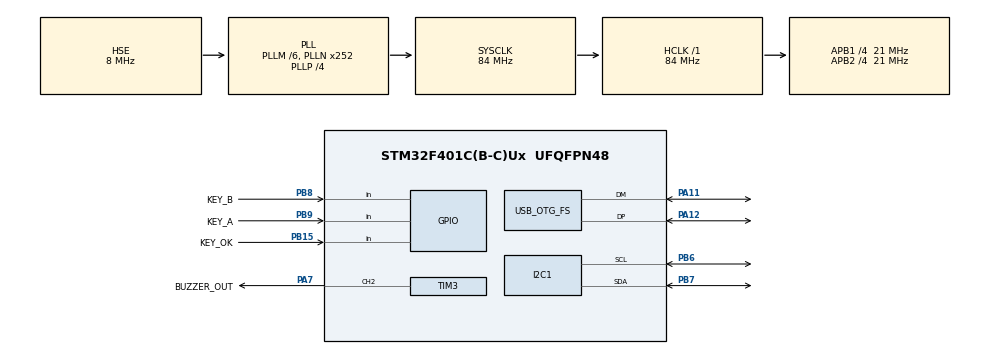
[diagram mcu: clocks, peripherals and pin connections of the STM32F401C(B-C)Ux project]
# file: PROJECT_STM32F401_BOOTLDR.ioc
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Dma.I2C1_RX.0.Direction=DMA_PERIPH_TO_MEMORY
Dma.I2C1_RX.0.FIFOMode=DMA_FIFOMODE_DISABLE
Dma.I2C1_RX.0.Instance=DMA1_Stream0
Dma.I2C1_RX.0.MemDataAlignment=DMA_MDATAALIGN_BYTE
Dma.I2C1_RX.0.MemInc=DMA_MINC_ENABLE
Dma.I2C1_RX.0.Mode=DMA_NORMAL
Dma.I2C1_RX.0.PeriphDataAlignment=DMA_PDATAALIGN_BYTE
Dma.I2C1_RX.0.PeriphInc=DMA_PINC_DISABLE
Dma.I2C1_RX.0.Priority=DMA_PRIORITY_LOW
Dma.I2C1_TX.1.Direction=DMA_MEMORY_TO_PERIPH
Dma.I2C1_TX.1.FIFOMode=DMA_FIFOMODE_DISABLE
Dma.I2C1_TX.1.Instance=DMA1_Stream6
Dma.I2C1_TX.1.MemDataAlignment=DMA_MDATAALIGN_BYTE
Dma.I2C1_TX.1.MemInc=DMA_MINC_ENABLE
Dma.I2C1_TX.1.Mode=DMA_NORMAL
Dma.I2C1_TX.1.PeriphDataAlignment=DMA_PDATAALIGN_BYTE
Dma.I2C1_TX.1.PeriphInc=DMA_PINC_DISABLE
Dma.I2C1_TX.1.Priority=DMA_PRIORITY_MEDIUM
Dma.Request0=I2C1_RX
Dma.Request1=I2C1_TX
I2C1.I2C_Mode=I2C_Fast
Mcu.Family=STM32F4
Mcu.Name=STM32F401C(B-C)Ux
Mcu.Package=UFQFPN48
Mcu.UserConstants=TREF_TEMP_ADC1_CHANNEL,ADC_CHANNEL_2;TEMP_TEMP_ADC1_CHANNEL,ADC_CHANNEL_8;TIM1_PSC_FAST_PWM,46978;TIM1_PSC_SLOW_PWM,65535;BUZZER_CHANNEL,TIM_CHANNEL_2;SCL1_Pin,GPIO_PIN_6;SDA1_Pin,GPIO_PIN_7;SCL1_GPIO_Port,GPIOB;SDA1_GPIO_Port,GPIOB;SCL3_Pin,GPIO_PIN_8;SDA3_Pin,GPIO_PIN_4;SCL3_GPIO_Port,GPIOA;SDA3_GPIO_Port,GPIOB
NVIC.DMA1_Stream0_IRQn=true\:5\:0\:true\:false\:true\:false\:true
NVIC.DMA1_Stream6_IRQn=true\:5\:0\:true\:false\:true\:false\:true
NVIC.I2C1_ER_IRQn=true\:15\:0\:true\:false\:true\:true\:true
NVIC.I2C1_EV_IRQn=true\:15\:0\:true\:false\:true\:true\:true
NVIC.OTG_FS_IRQn=true\:5\:0\:true\:false\:true\:true\:true
NVIC.PriorityGroup=NVIC_PRIORITYGROUP_4
NVIC.TIM3_IRQn=true\:0\:0\:false\:false\:true\:true\:true
NVIC.TIM4_IRQn=true\:0\:0\:false\:false\:true\:false\:true
NVIC.TimeBase=TIM4_IRQn
NVIC.TimeBaseIP=TIM4
PA11.Mode=Device_Only
PA11.Signal=USB_OTG_FS_DM
PA12.Mode=Device_Only
PA12.Signal=USB_OTG_FS_DP
PA13.Mode=Serial_Wire
PA13.Signal=SYS_JTMS-SWDIO
PA14.Mode=Serial_Wire
PA14.Signal=SYS_JTCK-SWCLK
PA7.GPIO_Label=BUZZER_OUT
PA7.GPIO_Speed=GPIO_SPEED_FREQ_HIGH
PA7.Signal=S_TIM3_CH2
PB15.GPIO_Label=KEY_OK
PB15.GPIO_PuPd=GPIO_PULLUP
PB15.Signal=GPIO_Input
PB6.GPIO_Pu=GPIO_PULLUP
PB6.Mode=I2C
PB6.Signal=I2C1_SCL
PB7.GPIO_Pu=GPIO_PULLUP
PB7.Mode=I2C
PB7.Signal=I2C1_SDA
PB8.GPIO_Label=KEY_B
PB8.Signal=GPIO_Input
PB9.GPIO_Label=KEY_A
PB9.GPIO_PuPd=GPIO_PULLUP
PB9.Signal=GPIO_Input
PH0\ -\ OSC_IN.Mode=HSE-External-Oscillator
PH0\ -\ OSC_IN.Signal=RCC_OSC_IN
PH1\ -\ OSC_OUT.Mode=HSE-External-Oscillator
PH1\ -\ OSC_OUT.Signal=RCC_OSC_OUT
ProjectManager.HeapSize=0x900
ProjectManager.StackSize=0x900
ProjectManager.TargetToolchain=STM32CubeIDE
RCC.48MHZClocksFreq_Value=48000000
RCC.AHBFreq_Value=84000000
RCC.APB1CLKDivider=RCC_HCLK_DIV4
RCC.APB1Freq_Value=21000000
RCC.APB1TimFreq_Value=42000000
RCC.APB2CLKDivider=RCC_HCLK_DIV4
RCC.APB2Freq_Value=21000000
RCC.APB2TimFreq_Value=42000000
RCC.CortexFreq_Value=84000000
RCC.HCLKFreq_Value=84000000
RCC.HSE_VALUE=8000000
RCC.HSI_VALUE=16000000
RCC.LSE_VALUE=32768
RCC.PLLM=6
RCC.PLLN=252
RCC.PLLP=RCC_PLLP_DIV4
RCC.PLLQ=7
RCC.SYSCLKFreq_VALUE=84000000
RCC.SYSCLKSource=RCC_SYSCLKSOURCE_PLLCLK
RCC.VCOOutputFreq_Value=336000000
SH.S_TIM3_CH2.0=TIM3_CH2,PWM Generation2 CH2
TIM3.Channel-PWM\ Generation2\ CH2=TIM_CHANNEL_2
TIM3.OCPolarity_2=TIM_OCPOLARITY_LOW
TIM3.Period=255
TIM3.Prescaler=41
USB_DEVICE.CLASS_NAME_FS=DFU
USB_DEVICE.USBD_DFU_APP_DEFAULT_ADD=0x08010000
USB_DEVICE.USBD_DFU_MEDIA=@Internal Flash   /0x08000000/03*016Ka,01*016Kg,01*064Kg,07*128Kg
USB_DEVICE.USBD_MAX_STR_DESC_SIZ=1021
USB_DEVICE.VirtualMode=Dfu
USB_DEVICE.VirtualModeFS=Dfu_FS
USB_OTG_FS.VirtualMode=Device_Only
VP_SYS_VS_tim4.Mode=TIM4
VP_USB_DEVICE_VS_USB_DEVICE_DFU_FS.Mode=DFU_FS
board=custom

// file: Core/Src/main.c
/* USER CODE BEGIN Header */
/**
  ******************************************************************************
  * @file           : main.c
  * @brief          : Main program body
  ******************************************************************************
  * @attention
  *
  * <h2><center>&copy; Copyright (c) 2021 STMicroelectronics.
  * All rights reserved.</center></h2>
  *
  * This software component is licensed by ST under BSD 3-Clause license,
  * the "License"; You may not use this file except in compliance with the
  * License. You may obtain a copy of the License at:
  *                        opensource.org/licenses/BSD-3-Clause
  *
  ******************************************************************************
  */
/* USER CODE END Header */
#include "main.h"

/* USER CODE BEGIN Includes */
#include "cppports.h"
#include "usbd_dfu_if.h"
/* USER CODE END Includes */

I2C_HandleTypeDef hi2c1;
DMA_HandleTypeDef hdma_i2c1_rx;
DMA_HandleTypeDef hdma_i2c1_tx;

TIM_HandleTypeDef htim3;

void SystemClock_Config(void);
static void MX_GPIO_Init(void);
static void MX_DMA_Init(void);
static void MX_I2C1_Init(void);
static void MX_TIM3_Init(void);

int main(void)
{

  /* MCU Configuration--------------------------------------------------------*/

  /* Reset of all peripherals, Initializes the Flash interface and the Systick. */
  HAL_Init();

  /* Configure the system clock */
  SystemClock_Config();

  /* USER CODE BEGIN SysInit */
  //__HAL_RCC_I2C3_CLK_ENABLE();
  //__HAL_RCC_I2C1_CLK_ENABLE();

  //USB_Status_Init();

  /* USER CODE END SysInit */

  /* Initialize all configured peripherals */
  MX_GPIO_Init();
  MX_DMA_Init();
  MX_I2C1_Init();
  MX_TIM3_Init();
  /* USER CODE BEGIN 2 */
  resetWatchdog();
  //USB_Status_Init();	//复位USB引脚，放在亮屏处理中
  resetWatchdog();
  doGUIWork();

  /* USER CODE END 2 */

  /* Infinite loop */
  while (1)
  {

  }
}

void SystemClock_Config(void)
{
  RCC_OscInitTypeDef RCC_OscInitStruct = {0};
  RCC_ClkInitTypeDef RCC_ClkInitStruct = {0};

  /** Configure the main internal regulator output voltage
  */
  __HAL_RCC_PWR_CLK_ENABLE();
  __HAL_PWR_VOLTAGESCALING_CONFIG(PWR_REGULATOR_VOLTAGE_SCALE2);
  /** Initializes the RCC Oscillators according to the specified parameters
  * in the RCC_OscInitTypeDef structure.
  */
  RCC_OscInitStruct.OscillatorType = RCC_OSCILLATORTYPE_HSE;
  RCC_OscInitStruct.HSEState = RCC_HSE_ON;
  RCC_OscInitStruct.PLL.PLLState = RCC_PLL_ON;
  RCC_OscInitStruct.PLL.PLLSource = RCC_PLLSOURCE_HSE;
  RCC_OscInitStruct.PLL.PLLM = 6;
  RCC_OscInitStruct.PLL.PLLN = 252;
  RCC_OscInitStruct.PLL.PLLP = RCC_PLLP_DIV4;
  RCC_OscInitStruct.PLL.PLLQ = 7;
  if (HAL_RCC_OscConfig(&RCC_OscInitStruct) != HAL_OK)
  {
    Error_Handler();
  }
  /** Initializes the CPU, AHB and APB buses clocks
  */
  RCC_ClkInitStruct.ClockType = RCC_CLOCKTYPE_HCLK|RCC_CLOCKTYPE_SYSCLK
                              |RCC_CLOCKTYPE_PCLK1|RCC_CLOCKTYPE_PCLK2;
  RCC_ClkInitStruct.SYSCLKSource = RCC_SYSCLKSOURCE_PLLCLK;
  RCC_ClkInitStruct.AHBCLKDivider = RCC_SYSCLK_DIV1;
  RCC_ClkInitStruct.APB1CLKDivider = RCC_HCLK_DIV4;
  RCC_ClkInitStruct.APB2CLKDivider = RCC_HCLK_DIV4;

  if (HAL_RCC_ClockConfig(&RCC_ClkInitStruct, FLASH_LATENCY_2) != HAL_OK)
  {
    Error_Handler();
  }
}

static void MX_I2C1_Init(void)
{

  hi2c1.Instance = I2C1;
  hi2c1.Init.ClockSpeed = 400000;
  hi2c1.Init.DutyCycle = I2C_DUTYCYCLE_2;
  hi2c1.Init.OwnAddress1 = 0;
  hi2c1.Init.AddressingMode = I2C_ADDRESSINGMODE_7BIT;
  hi2c1.Init.DualAddressMode = I2C_DUALADDRESS_DISABLE;
  hi2c1.Init.OwnAddress2 = 0;
  hi2c1.Init.GeneralCallMode = I2C_GENERALCALL_DISABLE;
  hi2c1.Init.NoStretchMode = I2C_NOSTRETCH_DISABLE;
  if (HAL_I2C_Init(&hi2c1) != HAL_OK)
  {
    Error_Handler();
  }

}

static void MX_TIM3_Init(void)
{

  TIM_MasterConfigTypeDef sMasterConfig = {0};
  TIM_OC_InitTypeDef sConfigOC = {0};

  htim3.Instance = TIM3;
  htim3.Init.Prescaler = 41;
  htim3.Init.CounterMode = TIM_COUNTERMODE_UP;
  htim3.Init.Period = 255;
  htim3.Init.ClockDivision = TIM_CLOCKDIVISION_DIV1;
  htim3.Init.AutoReloadPreload = TIM_AUTORELOAD_PRELOAD_DISABLE;
  if (HAL_TIM_PWM_Init(&htim3) != HAL_OK)
  {
    Error_Handler();
  }
  sMasterConfig.MasterOutputTrigger = TIM_TRGO_RESET;
  sMasterConfig.MasterSlaveMode = TIM_MASTERSLAVEMODE_DISABLE;
  if (HAL_TIMEx_MasterConfigSynchronization(&htim3, &sMasterConfig) != HAL_OK)
  {
    Error_Handler();
  }
  sConfigOC.OCMode = TIM_OCMODE_PWM1;
  sConfigOC.Pulse = 0;
  sConfigOC.OCPolarity = TIM_OCPOLARITY_LOW;
  sConfigOC.OCFastMode = TIM_OCFAST_DISABLE;
  if (HAL_TIM_PWM_ConfigChannel(&htim3, &sConfigOC, TIM_CHANNEL_2) != HAL_OK)
  {
    Error_Handler();
  }
  HAL_TIM_MspPostInit(&htim3);

}

static void MX_DMA_Init(void)
{

  /* DMA controller clock enable */
  __HAL_RCC_DMA1_CLK_ENABLE();

  /* DMA interrupt init */
  /* DMA1_Stream0_IRQn interrupt configuration */
  HAL_NVIC_SetPriority(DMA1_Stream0_IRQn, 5, 0);
  HAL_NVIC_EnableIRQ(DMA1_Stream0_IRQn);
  /* DMA1_Stream6_IRQn interrupt configuration */
  HAL_NVIC_SetPriority(DMA1_Stream6_IRQn, 5, 0);
  HAL_NVIC_EnableIRQ(DMA1_Stream6_IRQn);

}

static void MX_GPIO_Init(void)
{
  GPIO_InitTypeDef GPIO_InitStruct = {0};

  /* GPIO Ports Clock Enable */
  __HAL_RCC_GPIOH_CLK_ENABLE();
  __HAL_RCC_GPIOA_CLK_ENABLE();
  __HAL_RCC_GPIOB_CLK_ENABLE();

  /*Configure GPIO pins : KEY_OK_Pin KEY_A_Pin */
  GPIO_InitStruct.Pin = KEY_OK_Pin|KEY_A_Pin;
  GPIO_InitStruct.Mode = GPIO_MODE_INPUT;
  GPIO_InitStruct.Pull = GPIO_PULLUP;
  HAL_GPIO_Init(GPIOB, &GPIO_InitStruct);

  /*Configure GPIO pin : KEY_B_Pin */
  GPIO_InitStruct.Pin = KEY_B_Pin;
  GPIO_InitStruct.Mode = GPIO_MODE_INPUT;
  GPIO_InitStruct.Pull = GPIO_NOPULL;
  HAL_GPIO_Init(KEY_B_GPIO_Port, &GPIO_InitStruct);

}

/* USER CODE BEGIN 4 */
void resetWatchdog() {
	//若没有MX_IWG_Init()，使用下面这句，会使flash不能正常储存
	//HAL_IWDG_Refresh(&hiwdg);
	;
}
/* USER CODE END 4 */

void HAL_TIM_PeriodElapsedCallback(TIM_HandleTypeDef *htim)
{
  if (htim->Instance == TIM4) {
    HAL_IncTick();
  }
}

void Error_Handler(void)
{
}

/************************ (C) COPYRIGHT STMicroelectronics *****END OF FILE****/
